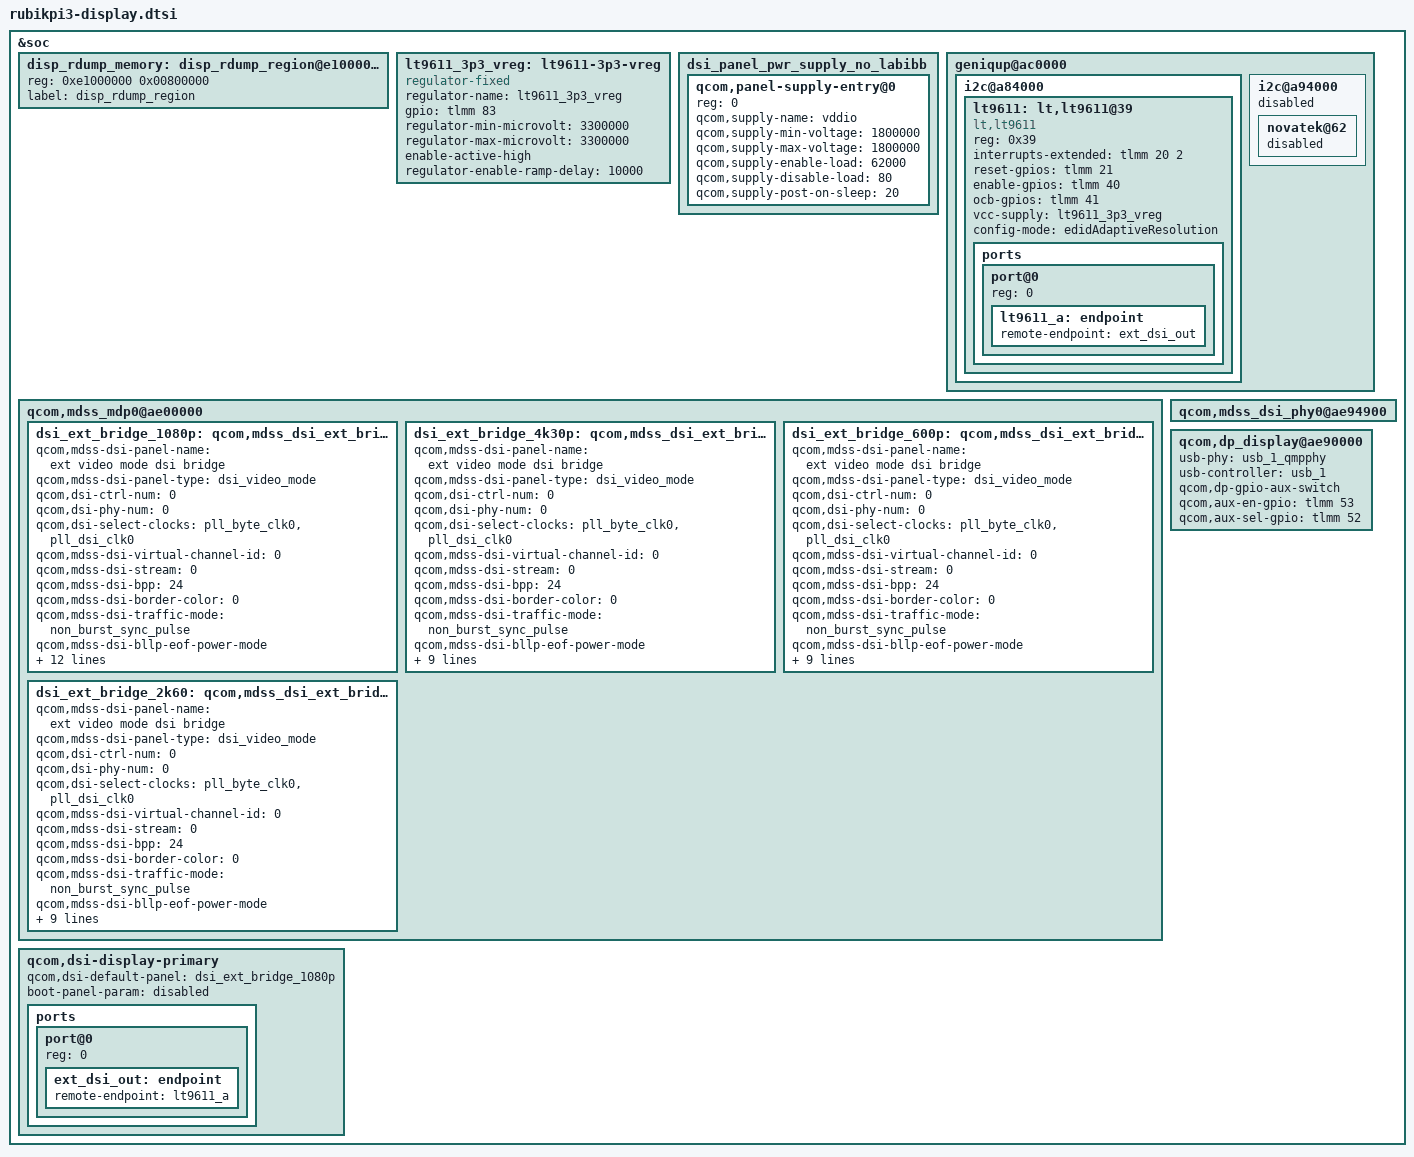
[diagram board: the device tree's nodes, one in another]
&soc {
	disp_rdump_memory: disp_rdump_region@e1000000 {
 		reg = <0xe1000000 0x00800000>;
		label = "disp_rdump_region";
	};

	lt9611_3p3_vreg: lt9611-3p3-vreg {
		compatible = "regulator-fixed";
		regulator-name = "lt9611_3p3_vreg";
		gpio = <&tlmm 83 0>;
		regulator-min-microvolt = <3300000>;
		regulator-max-microvolt = <3300000>;
		enable-active-high;
		regulator-enable-ramp-delay = <10000>;
	};

	dsi_panel_pwr_supply_no_labibb: dsi_panel_pwr_supply_no_labibb {
		#address-cells = <1>;
		#size-cells = <0>;

		qcom,panel-supply-entry@0 {
			reg = <0>;
			qcom,supply-name = "vddio";
			qcom,supply-min-voltage = <1800000>;
			qcom,supply-max-voltage = <1800000>;
			qcom,supply-enable-load = <62000>;
			qcom,supply-disable-load = <80>;
			qcom,supply-post-on-sleep = <20>;
		};
	};

	geniqup@ac0000 {
		i2c@a84000 {
			status = "ok";
			lt9611: lt,lt9611@39 {
				compatible = "lt,lt9611";
				reg = <0x39>;

				interrupts-extended = <&tlmm 20 2>;
				reset-gpios = <&tlmm 21 0>;
				enable-gpios = <&tlmm 40 0>;
				ocb-gpios = <&tlmm 41 0>;
				vcc-supply = <&lt9611_3p3_vreg>;
				config-mode = "edidAdaptiveResolution";

				ports {
					#address-cells = <1>;
					#size-cells = <0>;

					port@0 {
						reg = <0>;
						lt9611_a: endpoint {
							remote-endpoint = <&ext_dsi_out>;
						};
					};
				};
			};
		};

		i2c@a94000 {
			status = "disabled";
			novatek@62 {
				status = "disabled";
			};
		};
	};

	qcom,mdss_mdp0@ae00000 {
		dsi_ext_bridge_1080p: qcom,mdss_dsi_ext_bridge_1080p {
			qcom,mdss-dsi-panel-name = "ext video mode dsi bridge";
			qcom,mdss-dsi-panel-type = "dsi_video_mode";

			qcom,dsi-ctrl-num = <0>;
			qcom,dsi-phy-num = <0>;
			qcom,dsi-select-clocks = "pll_byte_clk0", "pll_dsi_clk0";

			qcom,mdss-dsi-virtual-channel-id = <0>;
			qcom,mdss-dsi-stream = <0>;
			qcom,mdss-dsi-bpp = <24>;
			qcom,mdss-dsi-border-color = <0>;
			qcom,mdss-dsi-traffic-mode = "non_burst_sync_pulse";
			qcom,mdss-dsi-bllp-eof-power-mode;
			qcom,mdss-dsi-bllp-power-mode;
			qcom,mdss-dsi-lane-0-state;
			qcom,mdss-dsi-lane-1-state;
			qcom,mdss-dsi-lane-2-state;
			qcom,mdss-dsi-lane-3-state;
			qcom,mdss-dsi-dma-trigger = "trigger_sw";
			qcom,mdss-dsi-mdp-trigger = "none";
			qcom,mdss-dsi-t-clk-post = <0x03>;
			qcom,mdss-dsi-t-clk-pre = <0x24>;
			qcom,mdss-dsi-force-clock-lane-hs;
			qcom,mdss-dsi-lp11-init;
			qcom,mdss-dsi-ext-bridge-mode;
		};

		dsi_ext_bridge_4k30p: qcom,mdss_dsi_ext_bridge_4k30p {
			qcom,mdss-dsi-panel-name = "ext video mode dsi bridge";
			qcom,mdss-dsi-panel-type = "dsi_video_mode";

			qcom,dsi-ctrl-num = <0>;
			qcom,dsi-phy-num = <0>;
			qcom,dsi-select-clocks = "pll_byte_clk0", "pll_dsi_clk0";

			qcom,mdss-dsi-virtual-channel-id = <0>;
			qcom,mdss-dsi-stream = <0>;
			qcom,mdss-dsi-bpp = <24>;
			qcom,mdss-dsi-border-color = <0>;
			qcom,mdss-dsi-traffic-mode = "non_burst_sync_pulse";
			qcom,mdss-dsi-bllp-eof-power-mode;
			qcom,mdss-dsi-bllp-power-mode;
			qcom,mdss-dsi-lane-0-state;
			qcom,mdss-dsi-lane-1-state;
			qcom,mdss-dsi-lane-2-state;
			qcom,mdss-dsi-lane-3-state;
			qcom,mdss-dsi-dma-trigger = "trigger_sw";
			qcom,mdss-dsi-mdp-trigger = "none";
			qcom,mdss-dsi-force-clock-lane-hs;
			qcom,mdss-dsi-ext-bridge-mode;
		};

		dsi_ext_bridge_600p: qcom,mdss_dsi_ext_bridge_600p {
			qcom,mdss-dsi-panel-name = "ext video mode dsi bridge";
			qcom,mdss-dsi-panel-type = "dsi_video_mode";

			qcom,dsi-ctrl-num = <0>;
			qcom,dsi-phy-num = <0>;
			qcom,dsi-select-clocks = "pll_byte_clk0", "pll_dsi_clk0";

			qcom,mdss-dsi-virtual-channel-id = <0>;
			qcom,mdss-dsi-stream = <0>;
			qcom,mdss-dsi-bpp = <24>;
			qcom,mdss-dsi-border-color = <0>;
			qcom,mdss-dsi-traffic-mode = "non_burst_sync_pulse";
			qcom,mdss-dsi-bllp-eof-power-mode;
			qcom,mdss-dsi-bllp-power-mode;
			qcom,mdss-dsi-lane-0-state;
			qcom,mdss-dsi-lane-1-state;
			qcom,mdss-dsi-lane-2-state;
			qcom,mdss-dsi-lane-3-state;
			qcom,mdss-dsi-dma-trigger = "trigger_sw";
			qcom,mdss-dsi-mdp-trigger = "none";
			qcom,mdss-dsi-force-clock-lane-hs;
			qcom,mdss-dsi-ext-bridge-mode;
		};

		dsi_ext_bridge_2k60: qcom,mdss_dsi_ext_bridge_2k60 {
			qcom,mdss-dsi-panel-name = "ext video mode dsi bridge";
			qcom,mdss-dsi-panel-type = "dsi_video_mode";

			qcom,dsi-ctrl-num = <0>;
			qcom,dsi-phy-num = <0>;
			qcom,dsi-select-clocks = "pll_byte_clk0", "pll_dsi_clk0";

			qcom,mdss-dsi-virtual-channel-id = <0>;
			qcom,mdss-dsi-stream = <0>;
			qcom,mdss-dsi-bpp = <24>;
			qcom,mdss-dsi-border-color = <0>;
			qcom,mdss-dsi-traffic-mode = "non_burst_sync_pulse";
			qcom,mdss-dsi-bllp-eof-power-mode;
			qcom,mdss-dsi-bllp-power-mode;
			qcom,mdss-dsi-lane-0-state;
			qcom,mdss-dsi-lane-1-state;
			qcom,mdss-dsi-lane-2-state;
			qcom,mdss-dsi-lane-3-state;
			qcom,mdss-dsi-dma-trigger = "trigger_sw";
			qcom,mdss-dsi-mdp-trigger = "none";
			qcom,mdss-dsi-force-clock-lane-hs;
			qcom,mdss-dsi-ext-bridge-mode;
		};
	};

	qcom,dsi-display-primary {
		/delete-property/ lab-supply;
		/delete-property/ ibb-supply;

		/delete-property/ qcom,dsi-pll-ssc-en;
		/delete-property/ qcom,dsi-pll-ssc-mode;

		qcom,dsi-default-panel = <&dsi_ext_bridge_1080p>;
		boot-panel-param = "disabled";

		ports {
			#address-cells = <1>;
			#size-cells = <0>;

			port@0 {
				reg = <0>;
				ext_dsi_out: endpoint {
					remote-endpoint = <&lt9611_a>;
				};
			};
		};
	};

	qcom,mdss_dsi_phy0@ae94900 {
		/delete-property/ qcom,dsi-pll-ssc-en;
		/delete-property/ qcom,dsi-pll-ssc-mode;
	};

	qcom,dp_display@ae90000 {
		usb-phy = <&usb_1_qmpphy>;
		usb-controller = <&usb_1>;
		qcom,dp-gpio-aux-switch;
		qcom,aux-en-gpio = <&tlmm 53 0>;
		qcom,aux-sel-gpio = <&tlmm 52 0>;
	};
};
